# ESP32-C3 register map
Vendor: ESPRESSIF SYSTEMS (SHANGHAI) CO., LTD.; Series: ESP32 C-Series; File version: 18
CPU: RV32IMC r0p0, little endian, no MPU, no FPU, 0 interrupt priority bits
Address unit: 32 bits
Registers are 32-bit, read-write, reset 0x0 unless marked. A register's access mark holds for its fields unless they carry their own. Offsets are from the block's base; [hi:lo] are bit positions; {n}, {i} and the like mark numbered series.

## SPI0 — SPI (Serial Peripheral Interface) Controller 0
Base 0x60003000
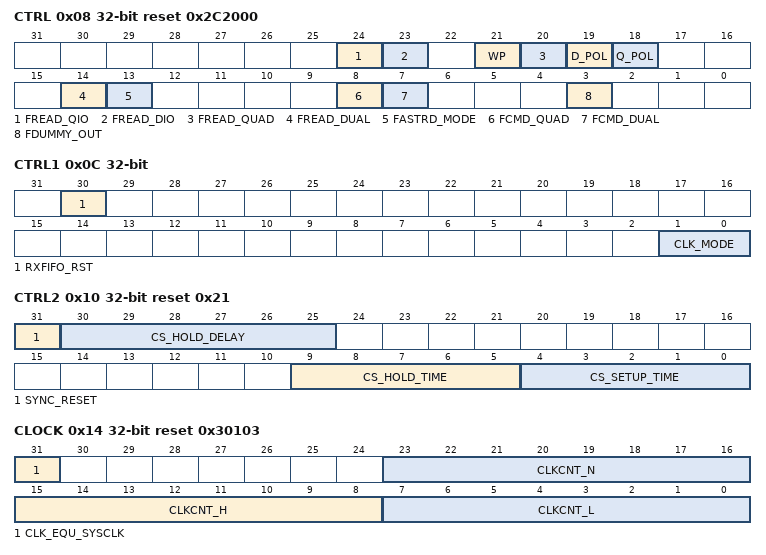
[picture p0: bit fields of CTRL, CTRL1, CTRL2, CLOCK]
0x08 CTRL reset 0x2C2000 — SPI0 control register.
  [24] FREAD_QIO — In the read operations address phase and read-data phase apply 4 signals. 1: enable 0: disable.
  [23] FREAD_DIO — In the read operations address phase and read-data phase apply 2 signals. 1: enable 0: disable.
  [21] WP — Write protect signal output when SPI is idle. 1: output high, 0: output low.
  [20] FREAD_QUAD — In the read operations read-data phase apply 4 signals. 1: enable 0: disable.
  [19] D_POL — The bit is used to set MOSI line polarity, 1: high 0, low
  [18] Q_POL — The bit is used to set MISO line polarity, 1: high 0, low
  [14] FREAD_DUAL — In the read operations, read-data phase apply 2 signals. 1: enable 0: disable.
  [13] FASTRD_MODE — This bit enable the bits: spi_mem_fread_qio, spi_mem_fread_dio, spi_mem_fread_qout and spi_mem_fread_dout. 1: enable 0: disable.
  [8] FCMD_QUAD — Apply 4 signals during command phase 1:enable 0: disable
  [7] FCMD_DUAL — Apply 2 signals during command phase 1:enable 0: disable
  [3] FDUMMY_OUT — In the dummy phase the signal level of spi is output by the spi controller.
0x0C CTRL1 access per field — SPI0 control1 register.
  [30] RXFIFO_RST wo — SPI0 RX FIFO reset signal.
  [1:0] CLK_MODE rw — SPI clock mode bits. 0: SPI clock is off when CS inactive 1: SPI clock is delayed one cycle after CS inactive 2: SPI clock is delayed two cycles after CS inactive 3: SPI clock is alwasy on.
0x10 CTRL2 access per field reset 0x21 — SPI0 control2 register.
  [31] SYNC_RESET wo — The FSM will be reset.
  [30:25] CS_HOLD_DELAY rw — These bits are used to set the minimum CS high time tSHSL between SPI burst transfer when accesses to flash. tSHSL is (SPI_MEM_CS_HOLD_DELAY[5:0] + 1) MSPI core clock cycles.
  [9:5] CS_HOLD_TIME rw — Spi cs signal is delayed to inactive by spi clock this bits are combined with spi_mem_cs_hold bit.
  [4:0] CS_SETUP_TIME rw — (cycles-1) of prepare phase by spi clock this bits are combined with spi_mem_cs_setup bit.
0x14 CLOCK reset 0x30103 — SPI clock division control register.
  [31] CLK_EQU_SYSCLK — Set this bit in 1-division mode.
  [23:16] CLKCNT_N — In the master mode it is the divider of spi_mem_clk. So spi_mem_clk frequency is system/(spi_mem_clkcnt_N+1)
  [15:8] CLKCNT_H — In the master mode it must be floor((spi_mem_clkcnt_N+1)/2-1).
  [7:0] CLKCNT_L — In the master mode it must be equal to spi_mem_clkcnt_N.
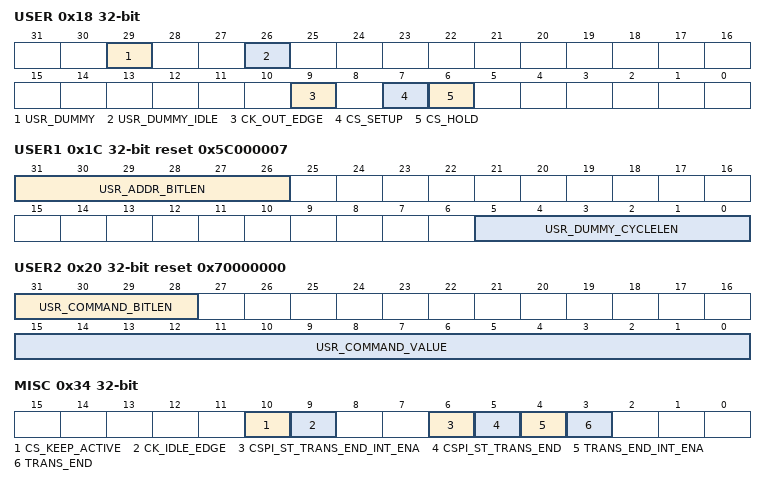
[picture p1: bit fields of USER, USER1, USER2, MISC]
0x18 USER — SPI0 user register.
  [29] USR_DUMMY — This bit enable the dummy phase of an operation.
  [26] USR_DUMMY_IDLE — spi clock is disable in dummy phase when the bit is enable.
  [9] CK_OUT_EDGE — the bit combined with spi_mem_mosi_delay_mode bits to set mosi signal delay mode.
  [7] CS_SETUP — spi cs is enable when spi is in prepare phase. 1: enable 0: disable.
  [6] CS_HOLD — spi cs keep low when spi is in done phase. 1: enable 0: disable.
0x1C USER1 reset 0x5C000007 — SPI0 user1 register.
  [31:26] USR_ADDR_BITLEN — The length in bits of address phase. The register value shall be (bit_num-1).
  [5:0] USR_DUMMY_CYCLELEN — The length in spi_mem_clk cycles of dummy phase. The register value shall be (cycle_num-1).
0x20 USER2 reset 0x70000000 — SPI0 user2 register.
  [31:28] USR_COMMAND_BITLEN — The length in bits of command phase. The register value shall be (bit_num-1)
  [15:0] USR_COMMAND_VALUE — The value of command.
0x2C RD_STATUS — SPI0 read control register.
  [23:16] WB_MODE — Mode bits in the flash fast read mode it is combined with spi_mem_fastrd_mode bit.
0x34 MISC — SPI0 misc register
  [10] CS_KEEP_ACTIVE — spi cs line keep low when the bit is set.
  [9] CK_IDLE_EDGE — 1: spi clk line is high when idle 0: spi clk line is low when idle
  [6] CSPI_ST_TRANS_END_INT_ENA — The bit is used to enable the interrupt of spi0_slv_st controlled transmitting is done.
  [5] CSPI_ST_TRANS_END — The bit is used to indicate the spi0_slv_st controlled transmitting is done.
  [4] TRANS_END_INT_ENA — The bit is used to enable the interrupt of spi0_mst_st controlled transmitting is done.
  [3] TRANS_END — The bit is used to indicate the spi0_mst_st controlled transmitting is done.
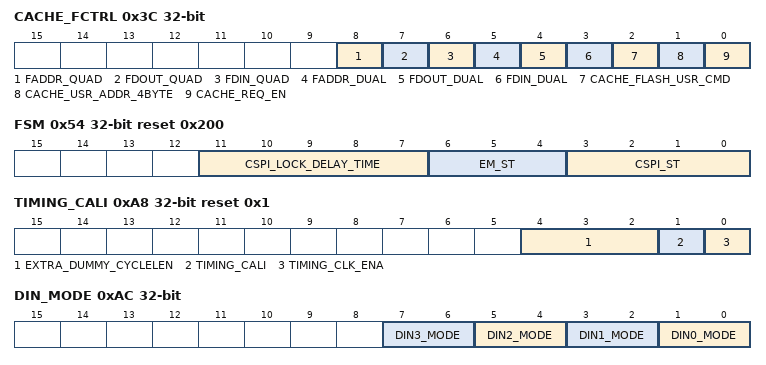
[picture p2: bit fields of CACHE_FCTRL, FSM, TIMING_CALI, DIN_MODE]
0x3C CACHE_FCTRL — SPI0 bit mode control register.
  [8] FADDR_QUAD — For SPI0 flash, address phase apply 4 signals. 1: enable 0: disable. The bit is the same with spi_mem_fread_qio.
  [7] FDOUT_QUAD — For SPI0 flash, dout phase apply 4 signals. 1: enable 0: disable. The bit is the same with spi_mem_fread_qio.
  [6] FDIN_QUAD — For SPI0 flash, din phase apply 4 signals. 1: enable 0: disable. The bit is the same with spi_mem_fread_qio.
  [5] FADDR_DUAL — For SPI0 flash, address phase apply 2 signals. 1: enable 0: disable. The bit is the same with spi_mem_fread_dio.
  [4] FDOUT_DUAL — For SPI0 flash, dout phase apply 2 signals. 1: enable 0: disable. The bit is the same with spi_mem_fread_dio.
  [3] FDIN_DUAL — For SPI0 flash, din phase apply 2 signals. 1: enable 0: disable. The bit is the same with spi_mem_fread_dio.
  [2] CACHE_FLASH_USR_CMD — For SPI0, cache read flash for user define command, 1: enable, 0:disable.
  [1] CACHE_USR_ADDR_4BYTE — For SPI0, cache read flash with 4 bytes address, 1: enable, 0:disable.
  [0] CACHE_REQ_EN — For SPI0, Cache access enable, 1: enable, 0:disable.
0x54 FSM access per field reset 0x200 — SPI0 FSM status register
  [11:7] CSPI_LOCK_DELAY_TIME rw — The lock delay time of SPI0/1 arbiter by spi0_slv_st, after PER is sent by SPI1.
  [6:4] EM_ST ro — The current status of SPI0 master FSM: spi0_mst_st. 0: idle state, 1:EM_CACHE_GRANT , 2: program/erase suspend state, 3: SPI0 read data state, 4: wait cache/EDMA sent data is stored in SPI0 TX FIFO, 5: SPI0 write data state.
  [3:0] CSPI_ST ro — The current status of SPI0 slave FSM: spi0_slv_st. 0: idle state, 1: preparation state, 2: send command state, 3: send address state, 4: wait state, 5: read data state, 6:write data state, 7: done state, 8: read data end state.
0xA8 TIMING_CALI reset 0x1 — SPI0 timing calibration register
  [4:2] EXTRA_DUMMY_CYCLELEN — add extra dummy spi clock cycle length for spi clock calibration.
  [1] TIMING_CALI — The bit is used to enable timing auto-calibration for all reading operations.
  [0] TIMING_CLK_ENA — The bit is used to enable timing adjust clock for all reading operations.
0xAC DIN_MODE — SPI0 input delay mode control register
  [2n+1:2n] DIN{n}_MODE (n=0..3) — the input signals are delayed by system clock cycles, 0: input without delayed, 1: input with the posedge of clk_apb,2 input with the negedge of clk_apb, 3: input with the posedge of clk_160, 4 input with the negedge of clk_160, 5: input with the spi_clk high edge, 6: input with the spi_clk low edge
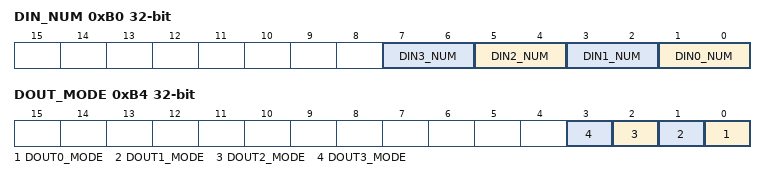
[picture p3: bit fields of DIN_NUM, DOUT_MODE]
0xB0 DIN_NUM — SPI0 input delay number control register
  [2n+1:2n] DIN{n}_NUM (n=0..3) — the input signals are delayed by system clock cycles, 0: delayed by 1 cycle, 1: delayed by 2 cycles,...
0xB4 DOUT_MODE — SPI0 output delay mode control register
  [n] DOUT{n}_MODE (n=0..3) — the output signals are delayed by system clock cycles, 0: output without delayed, 1: output with the posedge of clk_apb,2 output with the negedge of clk_apb, 3: output with the posedge of clk_160,4 output with the negedge of clk_160,5: output with the spi_clk high edge ,6: output with the spi_clk low edge
0xDC CLOCK_GATE reset 0x1 — SPI0 clk_gate register
  [0] CLK_EN — Register clock gate enable signal. 1: Enable. 0: Disable.
0xE0 CORE_CLK_SEL — SPI0 module clock select register
  [1:0] SPI01_CLK_SEL — When the digital system clock selects PLL clock and the frequency of PLL clock is 480MHz, the value of reg_spi01_clk_sel: 0: SPI0/1 module clock (clk) is 80MHz. 1: SPI0/1 module clock (clk) is 120MHz. 2: SPI0/1 module clock (clk) 160MHz. 3: Not used. When the digital system clock selects PLL clock and the frequency of PLL clock is 320MHz, the value of reg_spi01_clk_sel: 0: SPI0/1 module clock (clk) is 80MHz. 1: SPI0/1 module clock (clk) is 80MHz. 2: SPI0/1 module clock (clk) 160MHz. 3: Not used.
0x3FC DATE reset 0x2007130 — Version control register
  [27:0] DATE — SPI register version.
